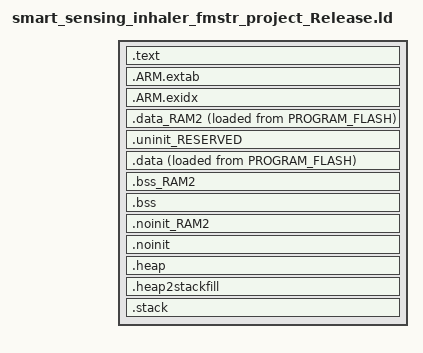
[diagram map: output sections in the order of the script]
/*
 * GENERATED FILE - DO NOT EDIT
 * Copyright 2008-2013 Code Red Technologies Ltd,
 * Copyright 2013-2024 NXP
 * Generated linker script file for MCXW716CxxxA
 * Created from linkscript.ldt by FMCreateLinkLibraries
 * Using Freemarker v2.3.30
 * MCUXpresso IDE v11.10.0 [Build 3148] [2024-07-03] on Nov 19, 2024, 2:27:53 PM
 */

INCLUDE "smart_sensing_inhaler_fmstr_project_Release_library.ld"
INCLUDE "smart_sensing_inhaler_fmstr_project_Release_memory.ld"

ENTRY(ResetISR)

SECTIONS
{
     /* MAIN TEXT SECTION */
    .text : ALIGN(4)
    {
        FILL(0xff)
        __vectors_start__ = ABSOLUTE(.) ;
        KEEP(*(.isr_vector))
        /* Global Section Table */
        . = ALIGN(4) ;
        __section_table_start = .;
        __data_section_table = .;
        LONG(LOADADDR(.data));
        LONG(    ADDR(.data));
        LONG(  SIZEOF(.data));
        LONG(LOADADDR(.data_RAM2));
        LONG(    ADDR(.data_RAM2));
        LONG(  SIZEOF(.data_RAM2));
        __data_section_table_end = .;
        __bss_section_table = .;
        LONG(    ADDR(.bss));
        LONG(  SIZEOF(.bss));
        LONG(    ADDR(.bss_RAM2));
        LONG(  SIZEOF(.bss_RAM2));
        __bss_section_table_end = .;
        __section_table_end = . ;
        /* End of Global Section Table */

        *(.after_vectors*)

       *(.text*)
       *(.rodata .rodata.* .constdata .constdata.*)
       . = ALIGN(4);
    } > PROGRAM_FLASH
    /*
     * for exception handling/unwind - some Newlib functions (in common
     * with C++ and STDC++) use this.
     */
    .ARM.extab : ALIGN(4)
    {
        *(.ARM.extab* .gnu.linkonce.armextab.*)
    } > PROGRAM_FLASH

    .ARM.exidx : ALIGN(4)
    {
        __exidx_start = .;
        *(.ARM.exidx* .gnu.linkonce.armexidx.*)
        __exidx_end = .;
    } > PROGRAM_FLASH
 
    _etext = .;
        
    /* DATA section for TCM_CODE */

    .data_RAM2 : ALIGN(4)
    {
        FILL(0xff)
        PROVIDE(__start_data_RAM2 = .) ;
        PROVIDE(__start_data_TCM_CODE = .) ;
        *(.ramfunc.$RAM2)
        *(.ramfunc.$TCM_CODE)
        *(.data.$RAM2)
        *(.data.$TCM_CODE)
        *(.data.$RAM2.*)
        *(.data.$TCM_CODE.*)
        . = ALIGN(4) ;
        PROVIDE(__end_data_RAM2 = .) ;
        PROVIDE(__end_data_TCM_CODE = .) ;
     } > TCM_CODE AT>PROGRAM_FLASH

    /* MAIN DATA SECTION */
    .uninit_RESERVED (NOLOAD) : ALIGN(4)
    {
        _start_uninit_RESERVED = .;
        KEEP(*(.bss.$RESERVED*))
       . = ALIGN(4) ;
        _end_uninit_RESERVED = .;
    } > TCM_SYS AT> TCM_SYS

    /* Main DATA section (TCM_SYS) */
    .data : ALIGN(4)
    {
       FILL(0xff)
       _data = . ;
       PROVIDE(__start_data_RAM = .) ;
       PROVIDE(__start_data_TCM_SYS = .) ;
       *(vtable)
       *(.ramfunc*)
       KEEP(*(CodeQuickAccess))
       KEEP(*(DataQuickAccess))
       *(RamFunction)
       *(.data*)
       . = ALIGN(4) ;
       _edata = . ;
       PROVIDE(__end_data_RAM = .) ;
       PROVIDE(__end_data_TCM_SYS = .) ;
    } > TCM_SYS AT>PROGRAM_FLASH

    /* BSS section for TCM_CODE */
    .bss_RAM2 (NOLOAD) : ALIGN(4)
    {
       PROVIDE(__start_bss_RAM2 = .) ;
       PROVIDE(__start_bss_TCM_CODE = .) ;
       *(.bss.$RAM2)
       *(.bss.$TCM_CODE)
       *(.bss.$RAM2.*)
       *(.bss.$TCM_CODE.*)
       . = ALIGN (. != 0 ? 4 : 1) ; /* avoid empty segment */
       PROVIDE(__end_bss_RAM2 = .) ;
       PROVIDE(__end_bss_TCM_CODE = .) ;
    } > TCM_CODE AT> TCM_CODE

    /* MAIN BSS SECTION */
    .bss (NOLOAD) : ALIGN(4)
    {
        _bss = .;
        PROVIDE(__start_bss_RAM = .) ;
        PROVIDE(__start_bss_TCM_SYS = .) ;
        *(.bss*)
        *(COMMON)
        . = ALIGN(4) ;
        _ebss = .;
        PROVIDE(__end_bss_RAM = .) ;
        PROVIDE(__end_bss_TCM_SYS = .) ;
        PROVIDE(end = .);
    } > TCM_SYS AT> TCM_SYS

    /* NOINIT section for TCM_CODE */
    .noinit_RAM2 (NOLOAD) : ALIGN(4)
    {
       PROVIDE(__start_noinit_RAM2 = .) ;
       PROVIDE(__start_noinit_TCM_CODE = .) ;
       *(.noinit.$RAM2)
       *(.noinit.$TCM_CODE)
       *(.noinit.$RAM2.*)
       *(.noinit.$TCM_CODE.*)
       . = ALIGN(4) ;
       PROVIDE(__end_noinit_RAM2 = .) ;
       PROVIDE(__end_noinit_TCM_CODE = .) ;
    } > TCM_CODE AT> TCM_CODE

    /* DEFAULT NOINIT SECTION */
    .noinit (NOLOAD): ALIGN(4)
    {
        _noinit = .;
        PROVIDE(__start_noinit_RAM = .) ;
        PROVIDE(__start_noinit_TCM_SYS = .) ;
        *(.noinit*)
         . = ALIGN(4) ;
        _end_noinit = .;
       PROVIDE(__end_noinit_RAM = .) ;
       PROVIDE(__end_noinit_TCM_SYS = .) ;        
    } > TCM_SYS AT> TCM_SYS

    /* Reserve and place Heap within memory map */
    _HeapSize = 0x1000;
    .heap (NOLOAD) :  ALIGN(4)
    {
        _pvHeapStart = .;
        . += _HeapSize;
        . = ALIGN(4);
        _pvHeapLimit = .;
    } > TCM_SYS

     _StackSize = 0x1000;
     /* Reserve space in memory for Stack */
    .heap2stackfill (NOLOAD) :
    {
        . += _StackSize;
    } > TCM_SYS
    /* Locate actual Stack in memory map */
    .stack ORIGIN(TCM_SYS) + LENGTH(TCM_SYS) - _StackSize - 0 (NOLOAD) :  ALIGN(4)
    {
        _vStackBase = .;
        . = ALIGN(4);
        _vStackTop = . + _StackSize;
    } > TCM_SYS

    /* Provide basic symbols giving location and size of main text
     * block, including initial values of RW data sections. Note that
     * these will need extending to give a complete picture with
     * complex images (e.g multiple Flash banks).
     */
    _image_start = LOADADDR(.text);
    _image_end = LOADADDR(.data) + SIZEOF(.data);
    _image_size = _image_end - _image_start;
}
